# SMS_LITE_AESEIP38T_0_SMS_LITE_TIFS_AES38T_4423C000h register map
Vendor: Texas Instruments
Peripheral module from a debugger description file (folder am62L).
Registers are 32-bit, write-only, reset values left out (the file's numbers can be read two ways) unless marked. A register's access mark holds for its fields unless they carry their own. Offsets are as the file gives them; lines under a group give offsets from that group; [hi:lo] are bit positions; {n}, {i} and the like mark numbered series; 'fields as' and 'values as' point back to an identical list; <NAME> marks a mode.

## SMS_LITE_TIFS_AES38T
0x00 SMS_LITE_TIFS_AES38T_S_AES_KEY2_6 — Secure Host Interface Bank
  [31:0] KEY — Key Data This register contains the 32-bit key data for the AES module. Initial key for XTS operations For a Host write operation, these registers must be written with the 128, 192 or 256-bit key for a subsequent AES operation. The key size equals the AES_KEY1 size. For a Host write operation, these registers must be written with the new values to be subsequently transferred to the AES Engine. OR Pre-calculated CBC-MAC third key (K3), used to perform a final XOR operation on the last input data block. OR This register is used to store intermediate values and must be initialized with zeroes when Writing a new GCM context. OR Used in f8/f9 algorithm Reset Source: sms_custom_rst_mod_g_rst_n
0x04 SMS_LITE_TIFS_AES38T_S_AES_KEY2_7 — Secure Host Interface Bank MSW for CBC-MAC and 256-bit XTS
  [31:0] KEY — Key Data This register contains the 32-bit key data for the AES module. Initial key for XTS operations For a Host write operation, these registers must be written with the 128, 192 or 256-bit key for a subsequent AES operation. The key size equals the AES_KEY1 size. For a Host write operation, these registers must be written with the new values to be subsequently transferred to the AES Engine. OR Pre-calculated CBC-MAC third key (K3), used to perform a final XOR operation on the last input data block. Reset Source: sms_custom_rst_mod_g_rst_n
0x08 SMS_LITE_TIFS_AES38T_S_AES_KEY2_4 — Secure Host Interface Bank LSW for CBC-MAC
  fields as SMS_LITE_TIFS_AES38T_S_AES_KEY2_7
0x0C SMS_LITE_TIFS_AES38T_S_AES_KEY2_5 — Secure Host Interface Bank MSW for 192-bit XTS
  fields as SMS_LITE_TIFS_AES38T_S_AES_KEY2_7
0x10 SMS_LITE_TIFS_AES38T_S_AES_KEY2_2 — Secure Host Interface Bank
  [31:0] KEY — Key Data This register contains the 32-bit key data for the AES module. Initial key for XTS operations For a Host write operation, these registers must be written with the 128, 192 or 256-bit key for a subsequent AES operation. The key size equals the AES_KEY1 size. For a Host write operation, these registers must be written with the new values to be subsequently transferred to the AES Engine. OR Pre-calculated CBC-MAC second key (K2), used to perform a final XOR operation on the last input data block. OR Hash key, can be calculated internal or written via these registers. Only used for GHASH (GCM) modes. For a Host write operation, these registers must be written with the new values to be subsequently transferred to the AES Engine. OR These 128-bits are used to store the CKKM / IKKM value for f8 OR These 128-bits are used to store the CKKM / IKKM value for f9 Reset Source: sms_custom_rst_mod_g_rst_n
0x14 SMS_LITE_TIFS_AES38T_S_AES_KEY2_3 — Secure Host Interface Bank MSW for CCM, CBC-MAC, Hash Key, and 128-bit XTS
  fields as SMS_LITE_TIFS_AES38T_S_AES_KEY2_2
0x18 SMS_LITE_TIFS_AES38T_S_AES_KEY2_0 — Secure Host Interface Bank LSW for XTS, CCM, CBC-MAC, and Hash Key
  fields as SMS_LITE_TIFS_AES38T_S_AES_KEY2_2
0x1C SMS_LITE_TIFS_AES38T_S_AES_KEY2_1 — Secure Host Interface Bank
  fields as SMS_LITE_TIFS_AES38T_S_AES_KEY2_2
0x20 SMS_LITE_TIFS_AES38T_S_AES_KEY1_6 — Secure Host Interface Bank
  [31:0] KEY — AES Key register. For a Host write operation, these registers must be written with the 128, 192 or 256-bit key for a subsequent AES operation. For a Host read operation, these registers return all-zeroes. The Host will typically write these registers in order, beginning with the AES_KEY_0 register. The key size (see the AES_MODE register) determines which key registers need to be populated, as indicated in the table below. Reset Source: sms_custom_rst_mod_g_rst_n
0x24 SMS_LITE_TIFS_AES38T_S_AES_KEY1_7 — Secure Host Interface Bank MSW for 256-bit key
  fields as SMS_LITE_TIFS_AES38T_S_AES_KEY1_6
0x28 SMS_LITE_TIFS_AES38T_S_AES_KEY1_4 — Secure Host Interface Bank
  fields as SMS_LITE_TIFS_AES38T_S_AES_KEY1_6
0x2C SMS_LITE_TIFS_AES38T_S_AES_KEY1_5 — Secure Host Interface Bank MSW for 192-bit key
  fields as SMS_LITE_TIFS_AES38T_S_AES_KEY1_6
0x30 SMS_LITE_TIFS_AES38T_S_AES_KEY1_2 — Secure Host Interface Bank
  fields as SMS_LITE_TIFS_AES38T_S_AES_KEY1_6
0x34 SMS_LITE_TIFS_AES38T_S_AES_KEY1_3 — Secure Host Interface Bank MSW for 128-bit key
  fields as SMS_LITE_TIFS_AES38T_S_AES_KEY1_6
0x38 SMS_LITE_TIFS_AES38T_S_AES_KEY1_0 — Secure Host Interface Bank LSW
  fields as SMS_LITE_TIFS_AES38T_S_AES_KEY1_6
0x3C SMS_LITE_TIFS_AES38T_S_AES_KEY1_1 — Secure Host Interface Bank
  fields as SMS_LITE_TIFS_AES38T_S_AES_KEY1_6
0x40 SMS_LITE_TIFS_AES38T_S_AES_IV_IN_0 rw — Secure Host Interface Bank LSW
  [31:0] DATA — For a Host write operation, these registers must be written with the new 128-bit IV to be subsequently transferred to the AES Engine. For a Host read operation, these registers contain the latest 128-bit IV output by the AES Engine. This value is incremented with 0x1, after first use when a new data block is submitted to the engine if CTR/ICM mode is selected. OR For XTS mode, this register must be written with the tweak location (_i_) of the data unit or (intermediate) tweak value (Tj), For a Host read operation, the IV_OUT register holds the next tweak value that is used for the next data block provided via the DATA_IN registers. This value can be re-used for continuation with the next block. It must be provide together with a _j_ of _0_ via the IV_IN registers. OR For f8 this field must be written with zeroes. OR (In case of GCM) For a Host write operation, these registers must be written with the new 128-bit IV to be subsequently transferred to the AES Engine. For a Host read operation, these registers contain the latest 128-bit IV output by the AES Engine. Note that bits [127:96] of the IV represent the initial counter value (which is _1_ for GCM) and must therefore be initialized to 0x01000000. This value is incremented with 0x1, after first use when a new data block is submitted to the engine. OR For CCM this field must be written with A0, this value constist of the concatenation of: A0-flags (5-bits of zero and 3-bits _L_), Nonce and counter value. _L_ must be a copy from the _L_ value of the AES_CTRL register. This _L_ indicates the width of the Nonce and counter. The loaded counter must be initialized to zero. The total width of A0 is 128-bit. Reset Source: sms_custom_rst_mod_g_rst_n
0x44 SMS_LITE_TIFS_AES38T_S_AES_IV_IN_1 rw — Secure Host Interface Bank
  fields as SMS_LITE_TIFS_AES38T_S_AES_IV_IN_0
0x48 SMS_LITE_TIFS_AES38T_S_AES_IV_IN_2 rw — Secure Host Interface Bank
  fields as SMS_LITE_TIFS_AES38T_S_AES_IV_IN_0
0x4C SMS_LITE_TIFS_AES38T_S_AES_IV_IN_3 rw — Secure Host Interface Bank MSW
  fields as SMS_LITE_TIFS_AES38T_S_AES_IV_IN_0
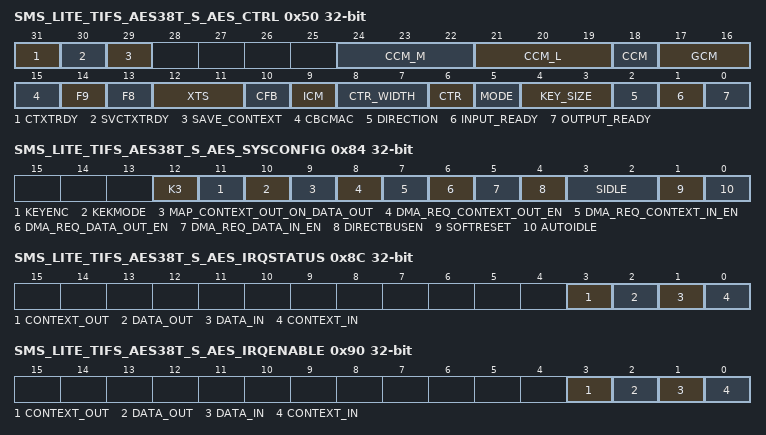
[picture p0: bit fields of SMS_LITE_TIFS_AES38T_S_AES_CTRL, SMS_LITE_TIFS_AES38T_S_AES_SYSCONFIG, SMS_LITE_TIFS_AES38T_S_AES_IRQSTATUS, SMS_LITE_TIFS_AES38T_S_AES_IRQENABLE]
0x50 SMS_LITE_TIFS_AES38T_S_AES_CTRL rw — Secure Host Interface Bank
  [31] CTXTRDY — Context Data Registers Ready Value Description 0 The context data registers are not ready to be overwritten. 1 The context data registers can be overwritten and the host is permitted to write the next context. Reset Source: sms_custom_rst_mod_g_rst_n
  [30] SVCTXTRDY — AES TAG/IV Block(s) Ready This bit is only asserted if the SAVE_CONTEXT bit is set to 1. This bit is mutual exclusive with the CTXTRDY bit. Value Description 0 AES authentication TAG and/or IV block(s) is/are not available. 1 Indicates the AES authentication TAG and /or IV block(s) is/are available for the host to retrieve. Reset Source: sms_custom_rst_mod_g_rst_n
  [29] SAVE_CONTEXT — TAG or Result IV Save If this bit is set, the CONTEXT_OUT interrupt bit is set in the AES_IRQSTATUS register if the operation is finished and related signals are enabled. Value Description 0 No effect. 1 Indicates an authentication TAG of result IV needs to be stored as a result context. Reset Source: sms_custom_rst_mod_g_rst_n
  [24:22] CCM_M — Counter with CBC-MAC (CCM)Defines M which indicates the length of the authentication field for CCM operations; the authentication field length equals two times the sum of CCM-M plus one. The AES Engine always returns a 128-bit authentication field, of which the M least significant bytes are valid. All values are supported. Reset Source: sms_custom_rst_mod_g_rst_n
  [21:19] CCM_L — Indicates the width of the length field for CCM operations; the length field in bytes equals the value of CMM-L plus one. Supported values for L are: Value Description 0x0 width = 0 0x1 width = 2 0x2 reserved 0x3 width = 4 0x4 - 0x6 reserved 0x7 width = 8 Reset Source: sms_custom_rst_mod_g_rst_n
  [18] CCM — AES-CCM Mode Enable Value Description 0 AES-CCM mode is not enabled. 1 AES-CCM mode enabled. This is a combined mode, using AES for both authentication and encryption. No additional mode selection is required. Reset Source: sms_custom_rst_mod_g_rst_n
  [17:16] GCM — AES-GCM Mode Enable This is a combined mode, using the Galois field-multiplier GF(2^128) for authentication and AES-CTR mode for encryption; the bits specify the GCM mode. Value Description 0x0 No operation 0x1 GHASH with H loaded and Y0-encrypted forced to zero 0x2 GHASH with H loaded and Y0-encrypted calculated internally 0x3 Autonomous GHASH (both H and Y0-encrypted calculated internally) Reset Source: sms_custom_rst_mod_g_rst_n
  [15] CBCMAC — AES-CBC MAC Enable The DIRECTION bit must be set to 1 for this mode. Value Description 0 AES-CBC MAC mode is not enabled. 1 AES-CBC MAC mode enabled. Reset Source: sms_custom_rst_mod_g_rst_n
  [14] F9 — AES f9 Mode Enable The AES key size must be set to 128-bit for this mode. Value Description 0 f9 mode is not enabled 1 f9 mode is enabled. Reset Source: sms_custom_rst_mod_g_rst_n
  [13] F8 — AES f8 Mode Enable, The KEY_SIZE must be set to 128-bit for this mode. Value Description 0 AES f8 mode is not enabled. 1 AES f8 mode is enabled. Reset Source: sms_custom_rst_mod_g_rst_n
  [12:11] XTS — AES-XTS Operation Enable The bits specify the XTS mode. Value Description 0x0 No operation 0x1 Previous/intermediate tweak value and j loaded (value is loaded via IV, j is loaded via the AAD length register) 0x2 Key2, n and j are loaded (n is loaded via IV, j is loaded via the AAD length register) 0x3 Key2 and n are loaded; j=0 (n is loaded via IV) Reset Source: sms_custom_rst_mod_g_rst_n
  [10] CFB — Full block AES cipher feedback mode (CFB128) Enable Value Description 0 AES-CFB mode is not enabled. 1 AES-CFB mode is enabled. Reset Source: sms_custom_rst_mod_g_rst_n
  [9] ICM — AES Integer Counter Mode (ICM) Enable This is a counter mode with a 16-bit wide counter. Value Description 0 AES-ICM mode is not enabled. 1 AES-ICM mode is enabled. Reset Source: sms_custom_rst_mod_g_rst_n
  [8:7] CTR_WIDTH — AES-CTR Mode Counter Width Value Description 0x0 Counter is 32 bits 0x1 Counter is 64 bits 0x2 Counter is 96 bits 0x3 Counter is 128 bits Reset Source: sms_custom_rst_mod_g_rst_n
  [6] CTR — Counter Mode This bit must also be set for GCM and CCM mode, when encryption/decryption is required. Value Description 0 Counter mode is not enabled. 1 Counter mode is enabled. Reset Source: sms_custom_rst_mod_g_rst_n
  [5] MODE — ECB/CBC Mode Value Description 0 ECB mode 1 CBC mode Reset Source: sms_custom_rst_mod_g_rst_n
  [4:3] KEY_SIZE — Key Size Value Description 0x0 reserved 0x1 Key is 128 bits 0x2 Key is 192 bits 0x3 Key is 256 bits Reset Source: sms_custom_rst_mod_g_rst_n
  [2] DIRECTION — Encryption/Decryption Selection If set to =1, an encrypt operation is performed. If set to 0, a decrypt operation is performed. DIRECTION Value Description 0 Decryption is selected. 1 Encryption is selected. Reset Source: sms_custom_rst_mod_g_rst_n
  [1] INPUT_READY — Input Ready Status Value Description 0 Input buffer is not empty. 1 Indicates that the 16-byte input buffer is empty, and the host is permitted to write the next block of data. Reset Source: sms_custom_rst_mod_g_rst_n
  [0] OUTPUT_READY — Output Ready Status Value Description 0 No AES output block is available. 1 An AES output block is available for the host to retrieve. Reset Source: sms_custom_rst_mod_g_rst_n
0x54 SMS_LITE_TIFS_AES38T_S_AES_C_LENGTH_0 rw — Secure Host Interface Bank LSW
  [31:0] LENGTH — Bits [60:0] of the crypto length registers (LSW and MSW) store the cryptographic data length in bytes for all modes. Once processing with this context is started, this length decrements to zero. Data lengths up to (2^61 - 1) bytes are allowed. For GCM, any value up to 2^36 - 32 bytes can be used. This is because a 32-bit counter mode is used; the maximum number of 128-bit blocks is 2^32 - 2, resulting in a maximum number of bytes of 2^36 - 32. A write to this register triggers the engine to start using this context. This is valid for all modes except GCM and CCM. Note that for the combined modes, this length does not include the authentication only data; the authentication length is specified in the AES_AUTH_LENGTH register below. All modes must have a length > 0. For the combined modes, it is allowed to have one of the lengths equal to zero. For the basic encryption modes (ECB/CBC/CTR/ICM/CFB128) it is allowed to program zero to the length field; in that case the length is assumed infinite. All data must be byte (8-bit) aligned for stream cipher modes; bit aligned data streams are not supported by the AES Engine. For block cipher modes, the data length must be programmed in multiples of the block cipher size, 16 bytes. For a Host read operation, these registers return all-zeroes. Reset Source: sms_custom_rst_mod_g_rst_n
0x58 SMS_LITE_TIFS_AES38T_S_AES_C_LENGTH_1 rw — Secure Host Interface Bank MSW
  fields as SMS_LITE_TIFS_AES38T_S_AES_C_LENGTH_0
0x5C SMS_LITE_TIFS_AES38T_S_AES_AUTH_LENGTH rw — Secure Host Interface Bank
  [31:0] AUTH — Bits [31:0] of the authentication length register store the authentication data length in bytes for combined modes only (GCM or CCM) Supported AAD-lengths for CCM are from 0 to (2^16 - 2^8) bytes. For GCM any value up to (2^32 - 1) bytes can be used. Once processing with this context is started, this length decrements to zero. A write to this register triggers the engine to start using this context for GCM and CCM. For XTS this register is optionally used to load _j_. Loading of _j_ is only required if _j_ != 0. _j_ is a 28-bit value and must be written to bits [31-4] of this register. _j_ represents the sequential number of the 128-bit block inside the data unit. For the first block in a unit, this value is zero. It is not required to provide a _j_ for each new data block within a unit. Note that it is possible to start with a _j_ unequal to zero; refer to Table 4 for more details. For a Host read operation, these registers return all-zeroes. Reset Source: sms_custom_rst_mod_g_rst_n
{0x60+4i} SMS_LITE_TIFS_AES38T_S_AES_DATA_IN_OUT_{i} rw (i=0..3) — Secure Host Interface Bank
  [31:0] DATA — The Data Input/Output Registers buffer the input/output data blocks to/from the AES Engine. Notice that the data input buffer (AES_DATA_IN_n) and data output buffer (AES_DATA_OUT_n) are mapped to the same address locations. Writes to these addresses load the Input Buffer while reads pull from the Output Buffer. Therefore, for write access, the data input buffer is written; for read access, the data output buffer is read. The data input buffer must be written prior to starting an operation. The data output buffer contains valid data on completion of an operation. All writes from, and reads to, these registers are tracked independently per direction and HIB. Therefore, any 128-bit data block can be split over multiple 32-bit word transfers, which can be mixed with other transfers over the external interface. Reset Source: sms_custom_rst_mod_g_rst_n
{0x70+4i} SMS_LITE_TIFS_AES38T_S_AES_TAG_OUT_{i} ro (i=0..3) — Secure Host Interface Bank
  [31:0] HASH — Bits [31:0] of the AES TAG registers store the authentication value for the combined and authentication only modes. For a Host read operation, these registers contain the last 128-bit TAG output of the AES Engine; the TAG is available until the next context is written. This register will only contain valid data if the TAG is available, when the store_ready bit from AES_CTRL register is set. During processing or for operations/modes that do not return a TAG, reads from this register returns data from the IV register. For operations that do return a TAG in the IV register (e.g. XTS), the IV register must be accessed directly. Reset Source: sms_custom_rst_mod_g_rst_n
0x80 SMS_LITE_TIFS_AES38T_S_AES_REV access not given — Secure Host Interface Bank
  [31:0] REVISION — Revision number Reset Source: sms_custom_rst_mod_g_rst_n (access R/0)
0x84 SMS_LITE_TIFS_AES38T_S_AES_SYSCONFIG rw — Secure Host Interface Bank
  [12] K3 — If this bit is set to zero, a regular cryptographic operation is performed. This bit may be set to one only if bit [4] of this register (direct_bus_en) and bit [11] of this register (key_enc) are cleared to zero. If this bit is one, the K3 (see description of bit [11]) key is used as key for the selected cryptographic operation. If this mode is selected, the key length is internally forced, using the internally stored kek_mode_len value (see description of bit [11]). Please refer to Appendix A.5 for details on the key selection mechanism. Note that for correct behavior of the core this bit should only be changed if the core is ready for a new context on the secure HIB. Reset Source: sms_custom_rst_mod_g_rst_n
  [11] KEYENC — If this bit is set to zero, a regular cryptographic operation is performed. This bit may be set to one only if bit [4] of this register (direct_bus_en) is cleared to zero. If this bit is 1, the K1 key is used for the selected crypto operation. The key length is forced, using the internally stored kek_mode_len value (see description of bit [10]). Depending on the internally stored kek_mode_id (see description of bit [10]), the following operations are possible: Stored kek_mode_id = 0: The selected encryption or decryption operation will be performed using K1 as key. The result data is provided in the data output register, as in a normal operation. Stored kek_mode_id = 1: The CBC mode will be forced, using a zero IV for the first block. Two cases must be distinguished: 1: If the selected operation is an encryption, the encrypted result is provided in the data output register, as it is a normal operation. 2: If the selected operation is a decryption, the decrypted result is automatically stored in a separate key register: to generate internal key K3. No output data is provided in this case; Reading from the data output register returns zeroes. The key size of K3 is inherited from the K1 key size. The length value that was used to generate K1 is internally stored and used for the generation of K3. When K3 is generated, the kek_mode_len bits are stored with K3. The k3 mode, see bit [12], makes use of the stored kek_mode_len to assure that K3 is used with the proper length. Please refer to Appendix A.5 for details on the key selection mechanism. Note that for correct behavior of the core this bit should only be changed if the core is ready for a new context on the secure HIB. Reset Source: sms_custom_rst_mod_g_rst_n
  [10] KEKMODE — If this bit is zero, the direct key is used directly for the selected cryptographic operation, if it is selected by enabling bit [4] (direct_bus_en) of this register. If the direct key is not selected, a regular operation is performed. This bit may be set to one only if bit [4] of this register (direct_bus_en) is set to _1_. If this bit is set to one while the direct key bit is selected, the direct key is XOR-ed with a predefined constant value9 before it is used as key for the cryptographic operation. If both bits are set to 1, the direction of the cryptographic operation is forced to ?CBC encryption? (independent of the programmed direction in the AES_CTRL register). The result of the operation with this XOR-ed key is automatically stored in a separate key register: KEK K1. No output data is provided in this case; Reading from the data output register returns zeroes. If this mode is selected, the cryptographic mode is internally forced to CBC. The desired K1 key size should be programmed with the kek_mode_len bits [16:15]. The kek_mode_id bit [14], selects the constant value to be XORed with the direct key. When K1 is generated, both the kek_mode_id and kek_mode_len bits are stored with K1. The key_enc mode, see bit [11], makes use of the stored kek_mode_id and kek_mode_len values to assure that K1 can only be used in the mode for where it was generated for. Please refer to Appendix A.5 for details on the key selection mechanism. Note that for correct behavior of the core, this bit should only be changed if the core is ready for a new context on the secure HIB. The result of the operation with this XOR-ed key is automatically stored in a separate internal key register (KEK). No output data is provided in this case; Reading from the data output register returns zeroes.If this mode is selected, the cryptographic mode should be set to ECB and the key size should be 128-bit. Note that for correct behavior of the core, this bit should only be changed if the core is ready for a new context Reset Source: sms_custom_rst_mod_g_rst_n
  [9] MAP_CONTEXT_OUT_ON_DATA_OUT — If set to '1' the two context out requests (dma_req_context_out_en, Bit [8] above, and context_out interrupt enable, Bit [3] of AES_IRQENABLE register) are mapped on the corresponding data output request bit. In this case, the original context out bit values are ignored. Therefore, when this bit is enabled and the dma_req_data_out_en (Bit [6]) is enabled, this DMA request is used for the context output and data output. Similarly if the data_out interrupt enable (Bit [2] of AES_IRQENABLE register) is enabled, this interrupt is used for context output and data output. Note that when context and data output request or interrupt are mapped on each other, the context output is always requested after the last data output. Reset Source: sms_custom_rst_mod_g_rst_n
  [8] DMA_REQ_CONTEXT_OUT_EN — DMA Request Context Out Enable If set to 1, the DMA context output request is enabled (for context data out, for example, TAG for authentication modes). Value Description 0 DMA disabled for context output request. 1 DMA enabled for context output request. Reset Source: sms_custom_rst_mod_g_rst_n
  [7] DMA_REQ_CONTEXT_IN_EN — DMA Request Context In Enable Value Description 0 DMA disabled for context input request. 1 DMA enabled for context input request. Reset Source: sms_custom_rst_mod_g_rst_n
  [6] DMA_REQ_DATA_OUT_EN — DMA Request Data Out Enable Value Description 0 DMA disabled for data output request. 1 DMA enabled for data output request. Reset Source: sms_custom_rst_mod_g_rst_n
  [5] DMA_REQ_DATA_IN_EN — DMA Request Data In Enable Value Description 0 DMA disabled for data input request. 1 DMA enabled for data input request. Reset Source: sms_custom_rst_mod_g_rst_n
  [4] DIRECTBUSEN — Direct Bus Enable Value Description 0 Use the key registers 1 Use the direct bus Reset Source: sms_custom_rst_mod_g_rst_n
  [3:2] SIDLE — Target Idle Mode Value Description 0x0 Force-idle mode 0x1 No-idle 0x2 Smart-idle 0x3 reserved Reset Source: sms_custom_rst_mod_g_rst_n
  [1] SOFTRESET — Soft reset Value Description 0 No operation 1 Start soft reset sequence Reset Source: sms_custom_rst_mod_g_rst_n
  [0] AUTOIDLE — If set to 1, the internal clocks are switched off when there is no processing to be done. This bit is only available on the sHIB. Reset Source: sms_custom_rst_mod_g_rst_n
0x88 SMS_LITE_TIFS_AES38T_S_AES_SYSSTATUS ro — Secure Host Interface Bank
  [0] RESETDONE — Reset Done Value Description 0 Reset is not complete. 1 Reset is has completed. Reset Source: sms_custom_rst_mod_g_rst_n
0x8C SMS_LITE_TIFS_AES38T_S_AES_IRQSTATUS rw — Secure Host Interface Bank
  [3] CONTEXT_OUT — Context Output Interrupt Status Value Description 0 Authentication tag (and IV) interrupt(s) is/are not active. 1 Authentication tag (and IV) interrupt(s) is/are active and the interrupt output has been triggered. Reset Source: sms_custom_rst_mod_g_rst_n
  [2] DATA_OUT — Data Out Interrupt Status Value Description 0 The data out interrupt is not active. 1 The data out interrupt is active and the interrupt output has been triggered. Reset Source: sms_custom_rst_mod_g_rst_n
  [1] DATA_IN — Data In Interrupt Status Value Description 0 The data in interrupt is not active. 1 The data in interrupt is active and the interrupt output has been triggered. Reset Source: sms_custom_rst_mod_g_rst_n
  [0] CONTEXT_IN — Context In Interrupt Status Value Description 0 The context in interrupt is not active. 1 The context in interrupt is active and the interrupt output has been triggered. Reset Source: sms_custom_rst_mod_g_rst_n
0x90 SMS_LITE_TIFS_AES38T_S_AES_IRQENABLE rw — Secure Host Interface Bank
  [3] CONTEXT_OUT — Context Out Interrupt Enable Value Description 0 Authentication tag (and IV) interrupt(s) is/are disabled. 1 Authentication tag (and IV) interrupt(s) is/are enabled. Reset Source: sms_custom_rst_mod_g_rst_n
  [2] DATA_OUT — Data Out Interrupt Enable Value Description 0 The data out interrupt is disabled. 1 The data out interrupt is enabled. Reset Source: sms_custom_rst_mod_g_rst_n
  [1] DATA_IN — Data In Interrupt Enable Value Description 0 The data in interrupt is disabled. 1 The data in interrupt is enabled. Reset Source: sms_custom_rst_mod_g_rst_n
  [0] CONTEXT_IN — Context In Interrupt Enable Value Description 0 The context in interrupt is disabled. 1 The context in interrupt is enabled. Reset Source: sms_custom_rst_mod_g_rst_n
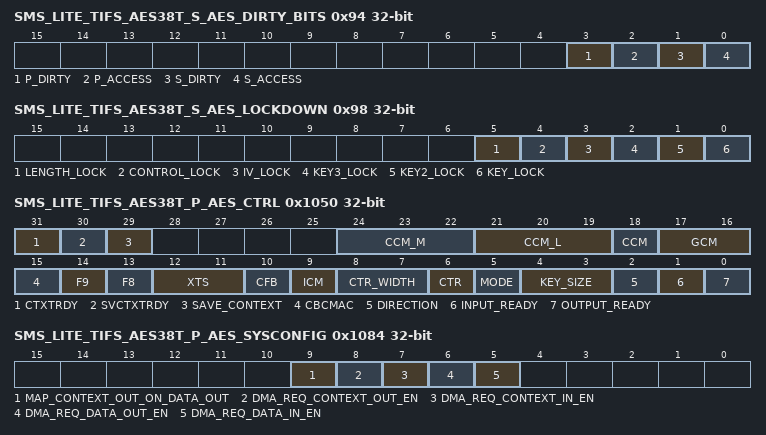
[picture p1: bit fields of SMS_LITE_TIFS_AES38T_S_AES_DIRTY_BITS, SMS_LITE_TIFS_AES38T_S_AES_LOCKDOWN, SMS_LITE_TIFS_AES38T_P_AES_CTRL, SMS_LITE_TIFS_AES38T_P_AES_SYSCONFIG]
0x94 SMS_LITE_TIFS_AES38T_S_AES_DIRTY_BITS rw — Secure Host Interface Bank
  [3] P_DIRTY — This bit is set to 1 by the module if any of the AES_P_* registers is written. Reset Source: sms_custom_rst_mod_g_rst_n
  [2] P_ACCESS — This bit is set to 1 by the module if any of the AES_P_* registers is read. Reset Source: sms_custom_rst_mod_g_rst_n
  [1] S_DIRTY — AES Dirty Bit This bit must be written to a 1 to clear. Value Description 0 No AES registers have been written. 1 Indicates when any of the AES_x registers have been written (except for the AES_DIRTYBITS register). Reset Source: sms_custom_rst_mod_g_rst_n
  [0] S_ACCESS — AES Access Bit This bit must be written to a 1 to clear. Value Description 0 No AES registers have been read. 1 Indicates when any of the AES_x registers have been read (except for the AES_DIRTYBITS register). Reset Source: sms_custom_rst_mod_g_rst_n
0x98 SMS_LITE_TIFS_AES38T_S_AES_LOCKDOWN rw — Secure Host Interface Bank
  [5] LENGTH_LOCK — If set to 1 the pHIB length registers can not be written (this lock involves word address 0x54 up to 0x5C). Reset Source: sms_custom_rst_mod_g_rst_n
  [4] CONTROL_LOCK — If set to 1 the pHIB control register can not be written (this lock involves word address 0x50). Reset Source: sms_custom_rst_mod_g_rst_n
  [3] IV_LOCK — If set to 1 the pHIB IV registers cannot be written (this lock involves word addresses 0x40 up to 0x4C). Reset Source: sms_custom_rst_mod_g_rst_n
  [2] KEY3_LOCK — If set to 1 the pHIB key3 registers cannot be written (this lock involves word addresses 0x30 up to 0x3C). Reset Source: sms_custom_rst_mod_g_rst_n
  [1] KEY2_LOCK — If set to 1 the pHIB key2 registers cannot be written (this lock involves word addresses 0x20 up to 0x2C). Reset Source: sms_custom_rst_mod_g_rst_n
  [0] KEY_LOCK — If set to 1 the pHIB key registers cannot be written (this lock involves word addresses 0x00 up to 0x1C). Reset Source: sms_custom_rst_mod_g_rst_n
0x9C SMS_LITE_TIFS_AES38T_Reserved_1 ro — Reserved
0x1000 SMS_LITE_TIFS_AES38T_P_AES_KEY2_6 — Public Host Interface Bank
  [31:0] P_AES_KEY2_6 — Key data Reset Source: sms_custom_rst_mod_g_rst_n
0x1004 SMS_LITE_TIFS_AES38T_P_AES_KEY2_7 — Public Host Interface Bank MSW for CBC-MAC and 256-bit XTS
  [31:0] P_AES_KEY2_7 — Key data Reset Source: sms_custom_rst_mod_g_rst_n
0x1008 SMS_LITE_TIFS_AES38T_P_AES_KEY2_4 — Public Host Interface Bank LSW for CBC-MAC
  [31:0] P_AES_KEY2_4 — Key data Reset Source: sms_custom_rst_mod_g_rst_n
0x100C SMS_LITE_TIFS_AES38T_P_AES_KEY2_5 — Public Host Interface Bank MSW for 192-bit XTS
  [31:0] P_AES_KEY2_5 — Key data Reset Source: sms_custom_rst_mod_g_rst_n
0x1010 SMS_LITE_TIFS_AES38T_P_AES_KEY2_2 — Public Host Interface Bank
  [31:0] P_AES_KEY2_2 — Key data Reset Source: sms_custom_rst_mod_g_rst_n
0x1014 SMS_LITE_TIFS_AES38T_P_AES_KEY2_3 — Public Host Interface Bank MSW for CCM, CBC-MAC, Hash Key, and 128-bit XTS
  [31:0] P_AES_KEY2_3 — Key data Reset Source: sms_custom_rst_mod_g_rst_n
0x1018 SMS_LITE_TIFS_AES38T_P_AES_KEY2_0 — Public Host Interface Bank LSW for XTS, CCM, CBC-MAC, and Hash Key
  [31:0] P_AES_KEY2_0 — Key data Reset Source: sms_custom_rst_mod_g_rst_n
0x101C SMS_LITE_TIFS_AES38T_P_AES_KEY2_1 — Public Host Interface Bank
  [31:0] P_AES_KEY2_1 — Key data Reset Source: sms_custom_rst_mod_g_rst_n
0x1020 SMS_LITE_TIFS_AES38T_P_AES_KEY1_6 — Public Host Interface Bank
  [31:0] P_AES_KEY1_6 — Key data Reset Source: sms_custom_rst_mod_g_rst_n
0x1024 SMS_LITE_TIFS_AES38T_P_AES_KEY1_7 — Public Host Interface Bank MSW for 256-bit key
  [31:0] P_AES_KEY1_7 — Key data Reset Source: sms_custom_rst_mod_g_rst_n
0x1028 SMS_LITE_TIFS_AES38T_P_AES_KEY1_4 — Public Host Interface Bank
  [31:0] P_AES_KEY1_4 — Key data Reset Source: sms_custom_rst_mod_g_rst_n
0x102C SMS_LITE_TIFS_AES38T_P_AES_KEY1_5 — Public Host Interface Bank MSW for 192-bit key
  [31:0] P_AES_KEY1_5 — Key data Reset Source: sms_custom_rst_mod_g_rst_n
0x1030 SMS_LITE_TIFS_AES38T_P_AES_KEY1_2 — Public Host Interface Bank
  [31:0] P_AES_KEY1_2 — Key data Reset Source: sms_custom_rst_mod_g_rst_n
0x1034 SMS_LITE_TIFS_AES38T_P_AES_KEY1_3 — Public Host Interface Bank MSW for 128-bit key
  [31:0] P_AES_KEY1_3 — Key data Reset Source: sms_custom_rst_mod_g_rst_n
0x1038 SMS_LITE_TIFS_AES38T_P_AES_KEY1_0 — Public Host Interface Bank LSW
  [31:0] P_AES_KEY1_0 — Key data Reset Source: sms_custom_rst_mod_g_rst_n
0x103C SMS_LITE_TIFS_AES38T_P_AES_KEY1_1 — Public Host Interface Bank
  [31:0] P_AES_KEY1_1 — Key data Reset Source: sms_custom_rst_mod_g_rst_n
0x1040 SMS_LITE_TIFS_AES38T_P_AES_IV_IN_0 rw — Public Host Interface Bank LSW
  [31:0] P_AES_IV_IN_0 — IV data Reset Source: sms_custom_rst_mod_g_rst_n
0x1044 SMS_LITE_TIFS_AES38T_P_AES_IV_IN_1 rw — Public Host Interface Bank
  [31:0] P_AES_IV_IN_1 — IV data Reset Source: sms_custom_rst_mod_g_rst_n
0x1048 SMS_LITE_TIFS_AES38T_P_AES_IV_IN_2 rw — Public Host Interface Bank
  [31:0] P_AES_IV_IN_2 — IV data Reset Source: sms_custom_rst_mod_g_rst_n
0x104C SMS_LITE_TIFS_AES38T_P_AES_IV_IN_3 rw — Public Host Interface Bank MSW
  [31:0] P_AES_IV_IN_3 — IV data Reset Source: sms_custom_rst_mod_g_rst_n
0x1050 SMS_LITE_TIFS_AES38T_P_AES_CTRL rw — Public Host Interface Bank
  fields as SMS_LITE_TIFS_AES38T_S_AES_CTRL
0x1054 SMS_LITE_TIFS_AES38T_P_AES_C_LENGTH_0 rw — Public Host Interface Bank LSW
  [31:0] P_AES_C_LENGTH_0 — Bits [60:0] of the crypto length registers (LSW and MSW) store the cryptographic data length in bytes for all modes. Once processing with this context is started, this length decrements to zero. Data lengths up to (2^61 - 1) bytes are allowed. For GCM, any value up to 2^36 - 32 bytes can be used. This is because a 32-bit counter mode is used; the maximum number of 128-bit blocks is 2^32 - 2, resulting in a maximum number of bytes of 2^36 - 32. A write to this register triggers the engine to start using this context. This is valid for all modes except GCM and CCM. Note that for the combined modes, this length does not include the authentication only data; the authentication length is specified in the AES_AUTH_LENGTH register below. All modes must have a length > 0. For the combined modes, it is allowed to have one of the lengths equal to zero. For the basic encryption modes (ECB/CBC/CTR/ICM/CFB128) it is allowed to program zero to the length field; in that case the length is assumed infinite. All data must be byte (8-bit) aligned for stream cipher modes; bit aligned data streams are not supported by the AES Engine. For block cipher modes, the data length must be programmed in multiples of the block cipher size, 16 bytes. For a Host read operation, these registers return all-zeroes. Reset Source: sms_custom_rst_mod_g_rst_n
0x1058 SMS_LITE_TIFS_AES38T_P_AES_C_LENGTH_1 rw — Public Host Interface Bank MSW
  [31:0] P_AES_C_LENGTH_1 — Bits [60:0] of the crypto length registers (LSW and MSW) store the cryptographic data length in bytes for all modes. Once processing with this context is started, this length decrements to zero. Data lengths up to (2^61 - 1) bytes are allowed. For GCM, any value up to 2^36 - 32 bytes can be used. This is because a 32-bit counter mode is used; the maximum number of 128-bit blocks is 2^32 - 2, resulting in a maximum number of bytes of 2^36 - 32. A write to this register triggers the engine to start using this context. This is valid for all modes except GCM and CCM. Note that for the combined modes, this length does not include the authentication only data; the authentication length is specified in the AES_AUTH_LENGTH register below. All modes must have a length > 0. For the combined modes, it is allowed to have one of the lengths equal to zero. For the basic encryption modes (ECB/CBC/CTR/ICM/CFB128) it is allowed to program zero to the length field; in that case the length is assumed infinite. All data must be byte (8-bit) aligned for stream cipher modes; bit aligned data streams are not supported by the AES Engine. For block cipher modes, the data length must be programmed in multiples of the block cipher size, 16 bytes. For a Host read operation, these registers return all-zeroes. Reset Source: sms_custom_rst_mod_g_rst_n
0x105C SMS_LITE_TIFS_AES38T_P_AES_AUTH_LENGTH rw — Public Host Interface Bank
  [31:0] P_AES_AUTH_LENGTH — Bits [31:0] of the authentication length register store the authentication data length in bytes for combined modes only (GCM or CCM) Supported AAD-lengths for CCM are from 0 to (2^16 - 2^8) bytes. For GCM any value up to (2^32 - 1) bytes can be used. Once processing with this context is started, this length decrements to zero. A write to this register triggers the engine to start using this context for GCM and CCM. For XTS this register is optionally used to load _j_. Loading of _j_ is only required if _j_ != 0. _j_ is a 28-bit value and must be written to bits [31-4] of this register. _j_ represents the sequential number of the 128-bit block inside the data unit. For the first block in a unit, this value is zero. It is not required to provide a _j_ for each new data block within a unit. Note that it is possible to start with a _j_ unequal to zero; refer to Table 4 for more details. For a Host read operation, these registers return all-zeroes. Reset Source: sms_custom_rst_mod_g_rst_n
{0x1060+4i} SMS_LITE_TIFS_AES38T_P_AES_DATA_IN_{i} rw (i=0..3) — Public Host Interface Bank
  [31:0] P_AES_DATA_IN_{i} — The Data Input/Output Registers buffer the input/output data blocks to/from the AES Engine. Notice that the data input buffer (AES_DATA_IN_n) and data output buffer (AES_DATA_OUT_n) are mapped to the same address locations. Writes to these addresses load the Input Buffer while reads pull from the Output Buffer. Therefore, for write access, the data input buffer is written; for read access, the data output buffer is read. The data input buffer must be written prior to starting an operation. The data output buffer contains valid data on completion of an operation. All writes from, and reads to, these registers are tracked independently per direction and HIB. Therefore, any 128-bit data block can be split over multiple 32-bit word transfers, which can be mixed with other transfers over the external interface. Reset Source: sms_custom_rst_mod_g_rst_n
{0x1070+4i} SMS_LITE_TIFS_AES38T_P_AES_TAG_OUT_{i} ro (i=0..3) — Public Host Interface Bank
  [31:0] P_AES_TAG_OUT_{i} — Bits [31:0] of the AES TAG registers store the authentication value for the combined and authentication only modes. For a Host read operation, these registers contain the last 128-bit TAG output of the AES Engine; the TAG is available until the next context is written. This register will only contain valid data if the TAG is available, when the store_ready bit from AES_CTRL register is set. During processing or for operations/modes that do not return a TAG, reads from this register returns data from the IV register. For operations that do return a TAG in the IV register (e.g. XTS), the IV register must be accessed directly. Reset Source: sms_custom_rst_mod_g_rst_n
0x1080 SMS_LITE_TIFS_AES38T_P_AES_REV ro — Public Host Interface Bank
  [31:0] P_AES_REV — Revision register Reset Source: sms_custom_rst_mod_g_rst_n
0x1084 SMS_LITE_TIFS_AES38T_P_AES_SYSCONFIG rw — Public Host Interface Bank
  [9] MAP_CONTEXT_OUT_ON_DATA_OUT — If set to '1' the two context out requests (dma_req_context_out_en, Bit [8] above, and context_out interrupt enable, Bit [3] of AES_IRQENABLE register) are mapped on the corresponding data output request bit. In this case, the original context out bit values are ignored. Therefore, when this bit is enabled and the dma_req_data_out_en (Bit [6]) is enabled, this DMA request is used for the context output and data output. Similarly if the data_out interrupt enable (Bit [2] of AES_IRQENABLE register) is enabled, this interrupt is used for context output and data output. Note that when context and data output request or interrupt are mapped on each other, the context output is always requested after the last data output. Reset Source: sms_custom_rst_mod_g_rst_n
  [8] DMA_REQ_CONTEXT_OUT_EN — DMA Request Context Out Enable If set to 1, the DMA context output request is enabled (for context data out, for example, TAG for authentication modes). Value Description 0 DMA disabled for context output request. 1 DMA enabled for context output request. Reset Source: sms_custom_rst_mod_g_rst_n
  [7] DMA_REQ_CONTEXT_IN_EN — DMA Request Context In Enable Value Description 0 DMA disabled for context input request. 1 DMA enabled for context input request. Reset Source: sms_custom_rst_mod_g_rst_n
  [6] DMA_REQ_DATA_OUT_EN — DMA Request Data Out Enable Value Description 0 DMA disabled for data output request. 1 DMA enabled for data output request. Reset Source: sms_custom_rst_mod_g_rst_n
  [5] DMA_REQ_DATA_IN_EN — DMA Request Data In Enable Value Description 0 DMA disabled for data input request. 1 DMA enabled for data input request. Reset Source: sms_custom_rst_mod_g_rst_n
0x1088 SMS_LITE_TIFS_AES38T_P_AES_SYSSTATUS ro — Public Host Interface Bank
  fields as SMS_LITE_TIFS_AES38T_S_AES_SYSSTATUS
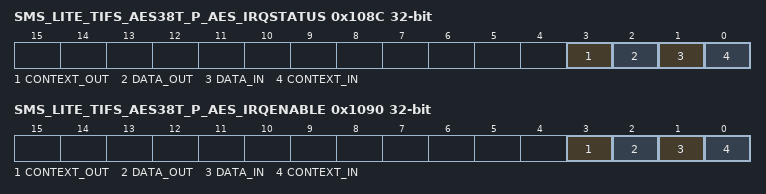
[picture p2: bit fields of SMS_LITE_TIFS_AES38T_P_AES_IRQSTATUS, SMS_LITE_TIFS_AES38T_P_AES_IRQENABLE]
0x108C SMS_LITE_TIFS_AES38T_P_AES_IRQSTATUS rw — Public Host Interface Bank
  fields as SMS_LITE_TIFS_AES38T_S_AES_IRQSTATUS
0x1090 SMS_LITE_TIFS_AES38T_P_AES_IRQENABLE rw — Public Host Interface Bank
  fields as SMS_LITE_TIFS_AES38T_S_AES_IRQENABLE
{0x108C+4i} SMS_LITE_TIFS_AES38T_Reserved_{i} ro (i=2..4) — Reserved
